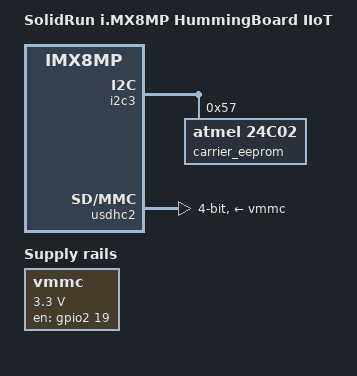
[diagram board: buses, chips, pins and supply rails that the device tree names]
// SPDX-License-Identifier: (GPL-2.0+ OR MIT)
/*
 * Copyright 2025 Josua Mayer <josua@solid-run.com>
 */

/dts-v1/;

#include <dt-bindings/phy/phy-imx8-pcie.h>

#include "imx8mp-sr-som.dtsi"

/ {
	model = "SolidRun i.MX8MP HummingBoard IIoT";
	compatible = "solidrun,imx8mp-hummingboard-iiot",
		     "solidrun,imx8mp-sr-som", "fsl,imx8mp";

	vmmc: regulator-mmc {
		compatible = "regulator-fixed";
		pinctrl-names = "default";
		pinctrl-0 = <&vmmc_pins>;
		regulator-name = "vmmc";
		regulator-min-microvolt = <3300000>;
		regulator-max-microvolt = <3300000>;
		gpio = <&gpio2 19 GPIO_ACTIVE_HIGH>;
		enable-active-high;
		startup-delay-us = <250>;
	};
};

&i2c3 {
	carrier_eeprom: eeprom@57{
		compatible = "atmel,24c02";
		reg = <0x57>;
		pagesize = <8>;
	};
};

&iomuxc {
	usdhc2_pins: usdhc2-pins {
		fsl,pins = <
			MX8MP_IOMUXC_SD2_CLK__USDHC2_CLK		0x190
			MX8MP_IOMUXC_SD2_CMD__USDHC2_CMD		0x1d0
			MX8MP_IOMUXC_SD2_DATA0__USDHC2_DATA0		0x1d0
			MX8MP_IOMUXC_SD2_DATA1__USDHC2_DATA1		0x1d0
			MX8MP_IOMUXC_SD2_DATA2__USDHC2_DATA2		0x1d0
			MX8MP_IOMUXC_SD2_DATA3__USDHC2_DATA3		0x1d0
			MX8MP_IOMUXC_GPIO1_IO04__USDHC2_VSELECT		0x140
			MX8MP_IOMUXC_SD2_CD_B__USDHC2_CD_B		0x140
		>;
	};

	usdhc2_100mhz_pins: usdhc2-100mhz-pins {
		fsl,pins = <
			MX8MP_IOMUXC_SD2_CLK__USDHC2_CLK		0x194
			MX8MP_IOMUXC_SD2_CMD__USDHC2_CMD		0x1d4
			MX8MP_IOMUXC_SD2_DATA0__USDHC2_DATA0		0x1d4
			MX8MP_IOMUXC_SD2_DATA1__USDHC2_DATA1		0x1d4
			MX8MP_IOMUXC_SD2_DATA2__USDHC2_DATA2		0x1d4
			MX8MP_IOMUXC_SD2_DATA3__USDHC2_DATA3		0x1d4
			MX8MP_IOMUXC_GPIO1_IO04__USDHC2_VSELECT 	0x140
			MX8MP_IOMUXC_SD2_CD_B__USDHC2_CD_B		0x140
		>;
	};

	usdhc2_200mhz_pins: usdhc2-200mhz-pins {
		fsl,pins = <
			MX8MP_IOMUXC_SD2_CLK__USDHC2_CLK		0x196
			MX8MP_IOMUXC_SD2_CMD__USDHC2_CMD		0x1d6
			MX8MP_IOMUXC_SD2_DATA0__USDHC2_DATA0		0x1d6
			MX8MP_IOMUXC_SD2_DATA1__USDHC2_DATA1		0x1d6
			MX8MP_IOMUXC_SD2_DATA2__USDHC2_DATA2		0x1d6
			MX8MP_IOMUXC_SD2_DATA3__USDHC2_DATA3		0x1d6
			MX8MP_IOMUXC_GPIO1_IO04__USDHC2_VSELECT		0x140
			MX8MP_IOMUXC_SD2_CD_B__USDHC2_CD_B		0x140
		>;
	};

	vmmc_pins: vmmc-pins {
		fsl,pins = <
			MX8MP_IOMUXC_SD2_RESET_B__GPIO2_IO19		0x41
		>;
	};
};

&usdhc2 {
	pinctrl-names = "default", "state_100mhz", "state_200mhz";
	pinctrl-0 = <&usdhc2_pins>;
	pinctrl-1 = <&usdhc2_100mhz_pins>;
	pinctrl-2 = <&usdhc2_200mhz_pins>;
	vmmc-supply = <&vmmc>;
	bus-width = <4>;
	cap-power-off-card;
	full-pwr-cycle;
	status = "okay";
};
